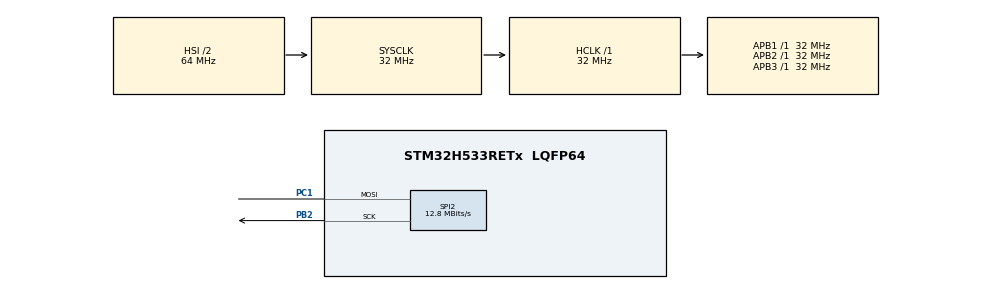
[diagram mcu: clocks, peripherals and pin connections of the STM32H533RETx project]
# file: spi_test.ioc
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BOOTPATH.BootPathName=LEGACY
BOOTPATH.UserSelectedBootPath=LEGACY
CORTEX_M33_NS.userName=CORTEX_M33
GPDMA1.CIRCULARMODE_GPDMACH5=DISABLE
GPDMA1.DIRECTION_GPDMACH5=DMA_MEMORY_TO_PERIPH
GPDMA1.IPHANDLE_GPDMACH5-SIMPLEREQUEST_GPDMACH5=__NULL
GPDMA1.REQUEST_GPDMACH5=GPDMA1_REQUEST_SPI2_TX
GPDMA1.SRCINC_GPDMACH5=DMA_SINC_INCREMENTED
Mcu.Family=STM32H5
Mcu.Name=STM32H533RETx
Mcu.Package=LQFP64
NUCLEO-H533RE.BUTTON=1
NUCLEO-H533RE.LD4=true
NUCLEO-H533RE.VCP=true
NVIC.EXTI13_IRQn=true\:0\:0\:false\:false\:true\:false\:true\:true
NVIC.GPDMA1_Channel5_IRQn=true\:0\:0\:false\:false\:true\:false\:true\:true
NVIC.PriorityGroup=NVIC_PRIORITYGROUP_4
NVIC.SPI2_IRQn=true\:0\:0\:false\:false\:true\:true\:true\:true
PA13(JTMS/SWDIO).GPIO_Label=SWDIO
PA13(JTMS/SWDIO).Signal=DEBUG_JTMS-SWDIO
PA14(JTCK/SWCLK).GPIO_Label=SWCLK
PA14(JTCK/SWCLK).Signal=DEBUG_JTCK-SWCLK
PA15(JTDI).GPIO_Label=JTDI
PA15(JTDI).Signal=DEBUG_JTDI
PA2.Signal=USART2_TX
PA3.Signal=USART2_RX
PB2.Mode=Simplex_Bidirectional_Master
PB2.Signal=SPI2_SCK
PB3(JTDO/TRACESWO).GPIO_Label=SWO
PB3(JTDO/TRACESWO).Signal=DEBUG_JTDO-SWO
PC1.Mode=Simplex_Bidirectional_Master
PC1.Signal=SPI2_MOSI
ProjectManager.HeapSize=0x200
ProjectManager.StackSize=0x400
ProjectManager.TargetToolchain=CMake
RCC.ADCFreq_Value=32000000
RCC.AHBFreq_Value=32000000
RCC.APB1Freq_Value=32000000
RCC.APB1TimFreq_Value=32000000
RCC.APB2Freq_Value=32000000
RCC.APB2TimFreq_Value=32000000
RCC.APB3Freq_Value=32000000
RCC.CSI_VALUE=4000000
RCC.CortexFreq_Value=32000000
RCC.EPOD_VALUE=4000000
RCC.HCLKFreq_Value=32000000
RCC.HSE_VALUE=25000000
RCC.HSI48_VALUE=48000000
RCC.HSI_VALUE=64000000
RCC.LSE_VALUE=32768
RCC.LSIRC_VALUE=32000
RCC.PLL1Q=5
RCC.PLLFRACN=0
RCC.PLLN=32
RCC.SYSCLKFreq_VALUE=32000000
RCC.USBFreq_Value=48000000
RCC.VCOOutputFreq_Value=128000000
SPI2.CalculateBaudRate=12.8 MBits/s
SPI2.DataSize=SPI_DATASIZE_8BIT
SPI2.Direction=SPI_DIRECTION_1LINE
SPI2.Mode=SPI_MODE_MASTER
SPI2.VirtualType=VM_MASTER
VP_BOOTPATH_VS_BOOTPATH.Mode=BP_Activate
VP_CORTEX_M33_NS_VS_Hclk.Mode=Hclk_Mode
VP_GPDMA1_VS_GPDMACH5.Mode=SIMPLEREQUEST_GPDMACH5
VP_ICACHE_VS_ICACHE.Mode=DefaultMode
VP_MEMORYMAP_VS_MEMORYMAP.Mode=CurAppReg
VP_NUCLEO-H533RE_VS_BSP_COMMON.Mode=COMMON
VP_PWR_VS_LPOM.Mode=PowerOptimisation
VP_PWR_VS_SECSignals.Mode=Security/Privilege
board=NUCLEO-H533RE

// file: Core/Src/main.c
/* USER CODE BEGIN Header */
/**
  ******************************************************************************
  * @file           : main.c
  * @brief          : Main program body
  ******************************************************************************
  * @attention
  *
  * Copyright (c) 2026 STMicroelectronics.
  * All rights reserved.
  *
  * This software is licensed under terms that can be found in the LICENSE file
  * in the root directory of this software component.
  * If no LICENSE file comes with this software, it is provided AS-IS.
  *
  ******************************************************************************
  */
/* USER CODE END Header */
#include "main.h"
#include "stm32h5xx_hal_def.h"
#include "stm32h5xx_nucleo.h"
#include <stdint.h>

COM_InitTypeDef BspCOMInit;

SPI_HandleTypeDef hspi2;
DMA_HandleTypeDef handle_GPDMA1_Channel5;

/* USER CODE BEGIN PV */

const uint8_t data[100] = {0x01};
volatile uint8_t spi_tx_done = 1;

uint32_t waitingCount = 0;
uint32_t newTransactionCount = 0;
volatile uint32_t completedTransactionCount = 0;

/* USER CODE END PV */

void SystemClock_Config(void);
static void MX_GPIO_Init(void);
static void MX_GPDMA1_Init(void);
static void MX_ICACHE_Init(void);
static void MX_SPI2_Init(void);

int main(void)
{

  /* MCU Configuration--------------------------------------------------------*/

  /* Reset of all peripherals, Initializes the Flash interface and the Systick. */
  HAL_Init();

  /* Configure the system clock */
  SystemClock_Config();

  /* Initialize all configured peripherals */
  MX_GPIO_Init();
  MX_GPDMA1_Init();
  MX_ICACHE_Init();
  MX_SPI2_Init();

  /* Initialize leds */
  BSP_LED_Init(LED_GREEN);

  /* Initialize USER push-button, will be used to trigger an interrupt each time it's pressed.*/
  BSP_PB_Init(BUTTON_USER, BUTTON_MODE_EXTI);

  /* Initialize COM1 port (115200, 8 bits (7-bit data + 1 stop bit), no parity */
  BspCOMInit.BaudRate   = 115200;
  BspCOMInit.WordLength = COM_WORDLENGTH_8B;
  BspCOMInit.StopBits   = COM_STOPBITS_1;
  BspCOMInit.Parity     = COM_PARITY_NONE;
  BspCOMInit.HwFlowCtl  = COM_HWCONTROL_NONE;
  if (BSP_COM_Init(COM1, &BspCOMInit) != BSP_ERROR_NONE)
  {
    Error_Handler();
  }

  /* Infinite loop */
  /* USER CODE BEGIN WHILE */
  while (1)
  {
    if(spi_tx_done) {
      newTransactionCount++;
      // printf("Starting SPI\r\n");
      BSP_LED_Off(LED_GREEN);
      // HAL_Delay(1000);
      spi_tx_done = 0;
      BSP_LED_On(LED_GREEN);
      HAL_StatusTypeDef status = HAL_SPI_Transmit_DMA(&hspi2, data, 100);
      printf("%d\r\n", status);
    } else {
      printf("SPI busy\r\n");
      waitingCount++;
      BSP_LED_On(LED_GREEN);
    }

    /* USER CODE END WHILE */

  }
}

void SystemClock_Config(void)
{
  RCC_OscInitTypeDef RCC_OscInitStruct = {0};
  RCC_ClkInitTypeDef RCC_ClkInitStruct = {0};

  /** Configure the main internal regulator output voltage
  */
  __HAL_PWR_VOLTAGESCALING_CONFIG(PWR_REGULATOR_VOLTAGE_SCALE3);

  while(!__HAL_PWR_GET_FLAG(PWR_FLAG_VOSRDY)) {}

  /** Initializes the RCC Oscillators according to the specified parameters
  * in the RCC_OscInitTypeDef structure.
  */
  RCC_OscInitStruct.OscillatorType = RCC_OSCILLATORTYPE_HSI|RCC_OSCILLATORTYPE_CSI;
  RCC_OscInitStruct.HSIState = RCC_HSI_ON;
  RCC_OscInitStruct.HSIDiv = RCC_HSI_DIV2;
  RCC_OscInitStruct.HSICalibrationValue = RCC_HSICALIBRATION_DEFAULT;
  RCC_OscInitStruct.CSIState = RCC_CSI_ON;
  RCC_OscInitStruct.CSICalibrationValue = RCC_CSICALIBRATION_DEFAULT;
  RCC_OscInitStruct.PLL.PLLState = RCC_PLL_ON;
  RCC_OscInitStruct.PLL.PLLSource = RCC_PLL1_SOURCE_CSI;
  RCC_OscInitStruct.PLL.PLLM = 1;
  RCC_OscInitStruct.PLL.PLLN = 32;
  RCC_OscInitStruct.PLL.PLLP = 2;
  RCC_OscInitStruct.PLL.PLLQ = 5;
  RCC_OscInitStruct.PLL.PLLR = 2;
  RCC_OscInitStruct.PLL.PLLRGE = RCC_PLL1_VCIRANGE_2;
  RCC_OscInitStruct.PLL.PLLVCOSEL = RCC_PLL1_VCORANGE_WIDE;
  RCC_OscInitStruct.PLL.PLLFRACN = 0;
  if (HAL_RCC_OscConfig(&RCC_OscInitStruct) != HAL_OK)
  {
    Error_Handler();
  }

  /** Initializes the CPU, AHB and APB buses clocks
  */
  RCC_ClkInitStruct.ClockType = RCC_CLOCKTYPE_HCLK|RCC_CLOCKTYPE_SYSCLK
                              |RCC_CLOCKTYPE_PCLK1|RCC_CLOCKTYPE_PCLK2
                              |RCC_CLOCKTYPE_PCLK3;
  RCC_ClkInitStruct.SYSCLKSource = RCC_SYSCLKSOURCE_HSI;
  RCC_ClkInitStruct.AHBCLKDivider = RCC_SYSCLK_DIV1;
  RCC_ClkInitStruct.APB1CLKDivider = RCC_HCLK_DIV1;
  RCC_ClkInitStruct.APB2CLKDivider = RCC_HCLK_DIV1;
  RCC_ClkInitStruct.APB3CLKDivider = RCC_HCLK_DIV1;

  if (HAL_RCC_ClockConfig(&RCC_ClkInitStruct, FLASH_LATENCY_1) != HAL_OK)
  {
    Error_Handler();
  }

  /** Configure the programming delay
  */
  __HAL_FLASH_SET_PROGRAM_DELAY(FLASH_PROGRAMMING_DELAY_0);
}

static void MX_GPDMA1_Init(void)
{

  /* Peripheral clock enable */
  __HAL_RCC_GPDMA1_CLK_ENABLE();

  /* GPDMA1 interrupt Init */
    HAL_NVIC_SetPriority(GPDMA1_Channel5_IRQn, 0, 0);
    HAL_NVIC_EnableIRQ(GPDMA1_Channel5_IRQn);

}

static void MX_ICACHE_Init(void)
{

  /** Enable instruction cache (default 2-ways set associative cache)
  */
  if (HAL_ICACHE_Enable() != HAL_OK)
  {
    Error_Handler();
  }

}

static void MX_SPI2_Init(void)
{

  /* SPI2 parameter configuration*/
  hspi2.Instance = SPI2;
  hspi2.Init.Mode = SPI_MODE_MASTER;
  hspi2.Init.Direction = SPI_DIRECTION_1LINE;
  hspi2.Init.DataSize = SPI_DATASIZE_8BIT;
  hspi2.Init.CLKPolarity = SPI_POLARITY_LOW;
  hspi2.Init.CLKPhase = SPI_PHASE_1EDGE;
  hspi2.Init.NSS = SPI_NSS_SOFT;
  hspi2.Init.BaudRatePrescaler = SPI_BAUDRATEPRESCALER_2;
  hspi2.Init.FirstBit = SPI_FIRSTBIT_MSB;
  hspi2.Init.TIMode = SPI_TIMODE_DISABLE;
  hspi2.Init.CRCCalculation = SPI_CRCCALCULATION_DISABLE;
  hspi2.Init.CRCPolynomial = 0x7;
  hspi2.Init.NSSPMode = SPI_NSS_PULSE_ENABLE;
  hspi2.Init.NSSPolarity = SPI_NSS_POLARITY_LOW;
  hspi2.Init.FifoThreshold = SPI_FIFO_THRESHOLD_01DATA;
  hspi2.Init.MasterSSIdleness = SPI_MASTER_SS_IDLENESS_00CYCLE;
  hspi2.Init.MasterInterDataIdleness = SPI_MASTER_INTERDATA_IDLENESS_00CYCLE;
  hspi2.Init.MasterReceiverAutoSusp = SPI_MASTER_RX_AUTOSUSP_DISABLE;
  hspi2.Init.MasterKeepIOState = SPI_MASTER_KEEP_IO_STATE_DISABLE;
  hspi2.Init.IOSwap = SPI_IO_SWAP_DISABLE;
  hspi2.Init.ReadyMasterManagement = SPI_RDY_MASTER_MANAGEMENT_INTERNALLY;
  hspi2.Init.ReadyPolarity = SPI_RDY_POLARITY_HIGH;
  if (HAL_SPI_Init(&hspi2) != HAL_OK)
  {
    Error_Handler();
  }

}

static void MX_GPIO_Init(void)
{

  /* GPIO Ports Clock Enable */
  __HAL_RCC_GPIOC_CLK_ENABLE();
  __HAL_RCC_GPIOB_CLK_ENABLE();
  __HAL_RCC_GPIOA_CLK_ENABLE();

}

void Error_Handler(void)
{
  __disable_irq();
  while (1)
  {
  }
}
